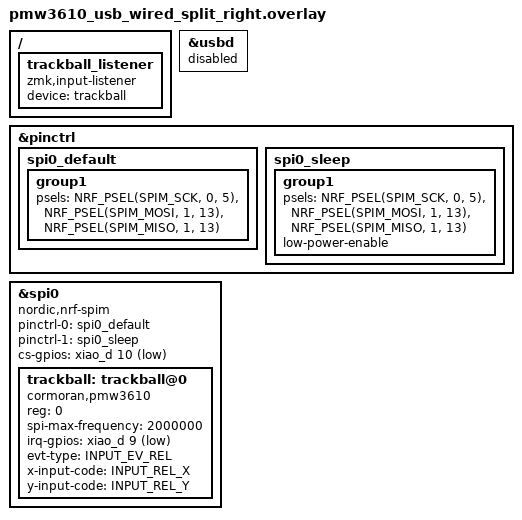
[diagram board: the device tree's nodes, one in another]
/* pmw3610_usb_wired_split PERIPHERAL half (right). See pmw3610_usb_wired_split.dtsi.
 *
 * Carries the real PMW3610 on SPIM0, wired to the same pins the Renode
 * peripheral platform models (SCK P0.05, MOSI/MISO P1.13, CS xiao_d 10 = P1.15,
 * IRQ xiao_d 9 = P1.14 -- see tests/renode/platforms/xiao_pmw3610*.repl). The
 * emulation drives a simulated PMW3610 (tests/renode/platforms/PMW3610.cs) on
 * this bus, so the peripheral's driver inits for real and answers relayed
 * GetInfo/ReadRegister requests over the wired split.
 *
 * USB is disabled here (the peripheral needs no USB); everything else (uart0
 * console, uart1 wired split, kscan/transform/layout) comes from the shared dtsi.
 */
#include "pmw3610_usb_wired_split.dtsi"

#include <zephyr/dt-bindings/input/input-event-codes.h>

&usbd {
	status = "disabled";
};

&pinctrl {
	spi0_default: spi0_default {
		group1 {
			psels = <NRF_PSEL(SPIM_SCK, 0, 5)>, <NRF_PSEL(SPIM_MOSI, 1, 13)>,
				<NRF_PSEL(SPIM_MISO, 1, 13)>;
		};
	};
	spi0_sleep: spi0_sleep {
		group1 {
			psels = <NRF_PSEL(SPIM_SCK, 0, 5)>, <NRF_PSEL(SPIM_MOSI, 1, 13)>,
				<NRF_PSEL(SPIM_MISO, 1, 13)>;
			low-power-enable;
		};
	};
};

&spi0 {
	compatible = "nordic,nrf-spim";
	status = "okay";
	pinctrl-0 = <&spi0_default>;
	pinctrl-1 = <&spi0_sleep>;
	pinctrl-names = "default", "sleep";
	cs-gpios = <&xiao_d 10 GPIO_ACTIVE_LOW>;

	trackball: trackball@0 {
		status = "okay";
		compatible = "cormoran,pmw3610";
		reg = <0>;
		spi-max-frequency = <2000000>;
		irq-gpios = <&xiao_d 9 (GPIO_ACTIVE_LOW | GPIO_PULL_UP)>;
		evt-type = <INPUT_EV_REL>;
		x-input-code = <INPUT_REL_X>;
		y-input-code = <INPUT_REL_Y>;
	};
};

/ {
	trackball_listener {
		compatible = "zmk,input-listener";
		device = <&trackball>;
	};
};
